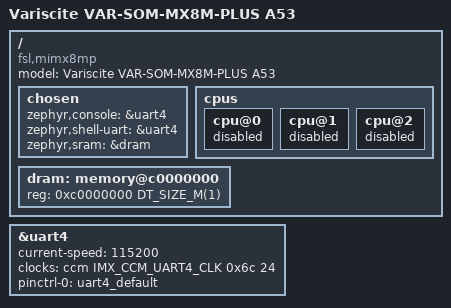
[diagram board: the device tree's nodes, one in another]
/*
 * Copyright 2025 Variscite Ltd.
 * Copyright 2021-2024 NXP
 *
 * SPDX-License-Identifier: Apache-2.0
 */

/dts-v1/;

#include <nxp/nxp_mimx8mp_a53.dtsi>
#include "imx8mp_var_som-pinctrl.dtsi"

/ {
	model = "Variscite VAR-SOM-MX8M-PLUS A53";
	compatible = "fsl,mimx8mp";

	chosen {
		zephyr,console = &uart4;
		zephyr,shell-uart = &uart4;
		/* sram node actually locates at DDR DRAM */
		zephyr,sram = &dram;
	};

	cpus {
		cpu@0 {
			status = "disabled";
		};
		cpu@1 {
			status = "disabled";
		};
		cpu@2 {
			status = "disabled";
		};
	};

	dram: memory@c0000000 {
		reg = <0xc0000000 DT_SIZE_M(1)>;
	};

};

&uart4 {
	status = "okay";
	current-speed = <115200>;
	clocks = <&ccm IMX_CCM_UART4_CLK 0x6c 24>;
	pinctrl-0 = <&uart4_default>;
	pinctrl-names = "default";
};
